VERSION ""

NS_ :

BS_:
BU_: BMSHV BMSLV SMUR SMUF SW VCU PCU LEM EBS IMU

BO_ 8 Arduino1: 8 IMU
   SG_ temp_1 : 0|32@1- (1,0) [0|0] "C" VCU
   SG_ temp_2 : 32|32@1- (1,0) [0|0] "C" VCU

BO_ 20 LVError: 1 BMSLV
   SG_ error_lv : 0|8@1+ (1,0) [0|1] "" Vector__XXX

BO_ 32 ResGO: 1 VCU
   SG_ go_signal : 0|1@1+ (1,0) [0|1] "" Vector__XXX

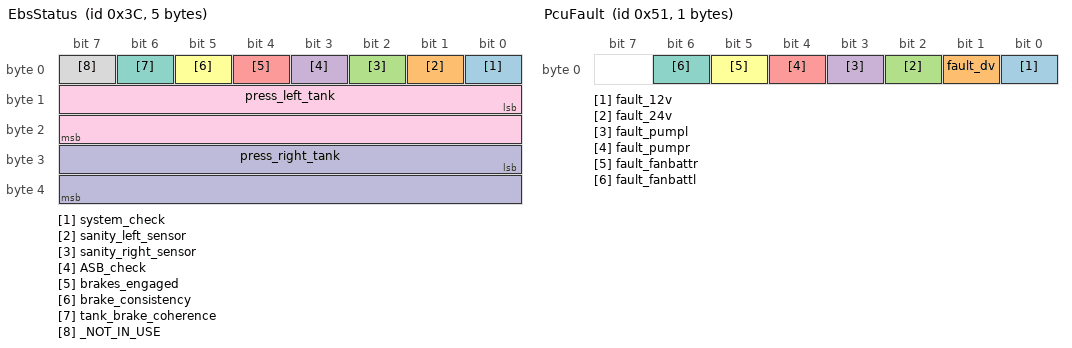
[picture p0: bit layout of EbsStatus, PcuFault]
BO_ 60 EbsStatus: 5 EBS
   SG_ system_check : 0|1@1+ (1,0) [0|1] "" Vector__XXX
   SG_ sanity_left_sensor : 1|1@1+ (1,0) [0|1] "" Vector__XXX
   SG_ sanity_right_sensor : 2|1@1+ (1,0) [0|1] "" Vector__XXX
   SG_ ASB_check : 3|1@1+ (1,0) [0|1] "" Vector__XXX
   SG_ brakes_engaged : 4|1@1+ (1,0) [0|1] "" Vector__XXX
   SG_ brake_consistency : 5|1@1+ (1,0) [0|1] "" Vector__XXX
   SG_ tank_brake_coherence : 6|1@1+ (1,0) [0|1] "" Vector__XXX
   SG_ _NOT_IN_USE : 7|1@1+ (1,0) [0|0] "" Vector__XXX
   SG_ press_left_tank : 8|16@1+ (0.001,0) [0|10] "Bar" Vector__XXX
   SG_ press_right_tank : 24|16@1+ (0.001,0) [0|10] "Bar" Vector__XXX

BO_ 65 Asms: 1 PCU
   SG_ Asms_sens : 0|1@1+ (1,0) [0|1] "High" Vector__XXX

BO_ 66 Asms_ack: 1 VCU
   SG_ Asms_sens : 0|1@1+ (1,0) [0|1] "High" Vector__XXX

BO_ 71 CarMission: 1 SW
   SG_ Mission : 0|3@1+ (1,0) [0|7] "" VCU

BO_ 81 PcuFault: 1 PCU
   SG_ fault_12v : 0|1@1+ (1,0) [0|1] "on" Vector__XXX
   SG_ fault_dv : 1|1@1+ (1,0) [0|1] "on" Vector__XXX
   SG_ fault_24v : 2|1@1+ (1,0) [0|1] "on" Vector__XXX
   SG_ fault_pumpl : 3|1@1+ (1,0) [0|1] "on" Vector__XXX
   SG_ fault_pumpr : 4|1@1+ (1,0) [0|1] "on" Vector__XXX
   SG_ fault_fanbattr : 5|1@1+ (1,0) [0|1] "on" Vector__XXX
   SG_ fault_fanbattl : 6|1@1+ (1,0) [0|1] "on" Vector__XXX

BO_ 82 Paddle: 1 SW
   SG_ regen : 0|8@1+ (1,0) [0|100] "%" VCU

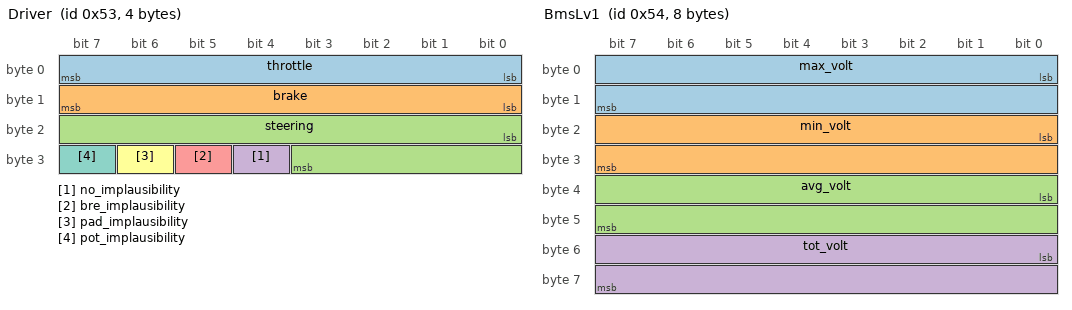
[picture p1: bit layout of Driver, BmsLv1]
BO_ 83 Driver: 4 SMUF
   SG_ throttle : 0|8@1+ (1,0) [0|100] "%" VCU
   SG_ brake : 8|8@1+ (1,0) [0|100] "%" VCU
   SG_ steering : 16|12@1- (1,0) [-120|120] "deg" VCU
   SG_ no_implausibility : 28|1@1+ (1,0) [0|0] "" Vector__XXX
   SG_ bre_implausibility : 29|1@1+ (1,0) [0|0] "" Vector__XXX
   SG_ pad_implausibility : 30|1@1+ (1,0) [0|0] "" Vector__XXX
   SG_ pot_implausibility : 31|1@1+ (1,0) [0|0] "" Vector__XXX

BO_ 84 BmsLv1: 8 BMSLV
   SG_ max_volt : 0|16@1+ (0.1,0) [0|0] "mV" VCU
   SG_ min_volt : 16|16@1+ (0.1,0) [0|0] "mV" VCU
   SG_ avg_volt : 32|16@1+ (0.1,0) [0|0] "mV" VCU
   SG_ tot_volt : 48|16@1+ (0.01,0) [0|100] "V" Vector__XXX

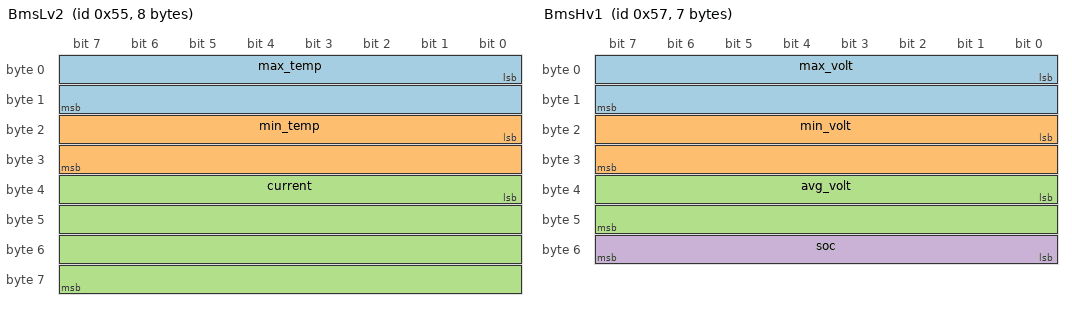
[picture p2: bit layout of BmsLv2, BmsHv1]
BO_ 85 BmsLv2: 8 BMSLV
   SG_ max_temp : 0|16@1+ (0.1,0) [0|0] "C" VCU
   SG_ min_temp : 16|16@1+ (0.1,0) [0|0] "C" VCU
   SG_ current : 32|32@1+ (0.1,0) [0|0] "mA" VCU

BO_ 87 BmsHv1: 7 BMSHV
   SG_ max_volt : 0|16@1+ (0.1,0) [0|0] "mV" VCU
   SG_ min_volt : 16|16@1+ (0.1,0) [0|0] "mV" VCU
   SG_ avg_volt : 32|16@1+ (0.1,0) [0|0] "mV" VCU
   SG_ soc : 48|8@1+ (1,0) [0|100] "%" VCU

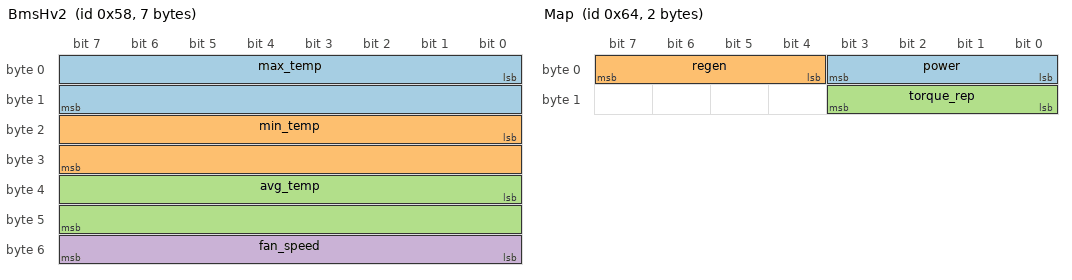
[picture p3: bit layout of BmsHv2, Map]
BO_ 88 BmsHv2: 7 BMSHV
   SG_ max_temp : 0|16@1+ (1,0) [0|0] "C" VCU
   SG_ min_temp : 16|16@1+ (1,0) [0|0] "C" VCU
   SG_ avg_temp : 32|16@1+ (1,0) [0|0] "C" VCU
   SG_ fan_speed : 48|8@1+ (1,0) [0|100] "%" VCU

BO_ 96 Imu1: 8 IMU
   SG_ acc_x : 0|32@1- (1,0) [0|0] "m/s^2" VCU
   SG_ acc_y : 32|32@1- (1,0) [0|0] "m/s^2" VCU

BO_ 97 Imu2: 8 IMU
   SG_ acc_z : 0|32@1- (1,0) [0|0] "m/s^2" VCU
   SG_ omega_x : 32|32@1- (1,0) [0|0] "rad/s" VCU

BO_ 98 Imu3: 8 IMU
   SG_ omega_y : 0|32@1- (1,0) [0|0] "rad/s" VCU
   SG_ omega_z : 32|32@1- (1,0) [0|0] "rad/s" VCU

BO_ 99 IMUCalib: 1 IMU
   SG_ start_imu_calibration : 0|1@1+ (1,0) [0|0] "" Vector__XXX

BO_ 100 Map: 2 SW
   SG_ power : 0|4@1+ (1,0) [1|12] "map" VCU
   SG_ regen : 4|4@1+ (1,0) [1|12] "map" VCU
   SG_ torque_rep : 8|4@1+ (1,0) [0|12] "map" Vector__XXX

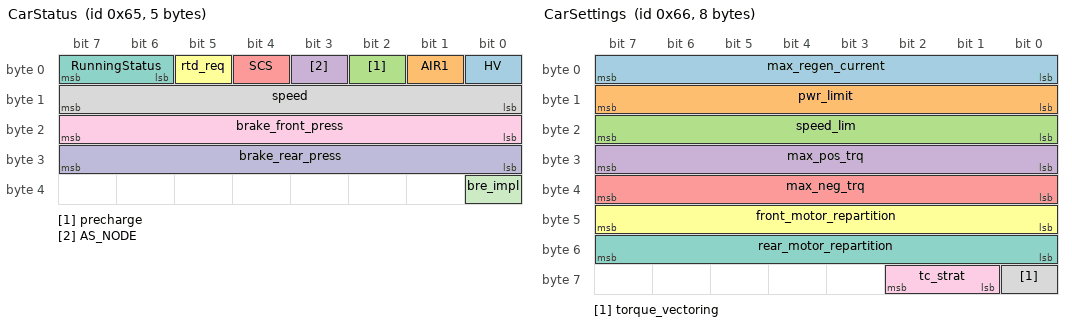
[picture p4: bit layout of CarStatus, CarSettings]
BO_ 101 CarStatus: 5 VCU
   SG_ HV : 0|1@1+ (1,0) [0|0] " Off/On" Vector__XXX
   SG_ AIR1 : 1|1@1+ (1,0) [0|0] " Closed/Open" Vector__XXX
   SG_ precharge : 2|1@1+ (1,0) [0|0] " Closed/Open" Vector__XXX
   SG_ AS_NODE : 3|1@1+ (1,0) [0|0] " Open/Closed" Vector__XXX
   SG_ SCS : 4|1@1+ (1,0) [0|0] " Open/Closed" Vector__XXX
   SG_ rtd_req : 5|1@1+ (1,0) [0|0] " Open/Closed" Vector__XXX
   SG_ RunningStatus : 6|2@1+ (1,0) [0|3] " Phase" Vector__XXX
   SG_ speed : 8|8@1+ (1,0) [0|0] " km/h" Vector__XXX
   SG_ brake_front_press : 16|8@1+ (0.25,0) [0|60] "Bar" Vector__XXX
   SG_ brake_rear_press : 24|8@1+ (0.25,0) [0|60] "Bar" Vector__XXX
   SG_ bre_impl : 32|1@1+ (1,0) [0|1] "" Vector__XXX

BO_ 102 CarSettings: 8 VCU
   SG_ max_regen_current : 0|8@1+ (1,0) [0|150] "A" Vector__XXX
   SG_ pwr_limit : 8|8@1+ (1,0) [0|80] "kW" Vector__XXX
   SG_ speed_lim : 16|8@1+ (1,0) [0|0] "krpm" Vector__XXX
   SG_ max_pos_trq : 24|8@1+ (1,0) [0|0] "Nm" Vector__XXX
   SG_ max_neg_trq : 32|8@1- (1,0) [0|0] "Nm" Vector__XXX
   SG_ front_motor_repartition : 40|8@1+ (1,0) [0|0] "%" Vector__XXX
   SG_ rear_motor_repartition : 48|8@1+ (1,0) [0|0] "%" Vector__XXX
   SG_ torque_vectoring : 56|1@1+ (1,0) [0|1] "on" Vector__XXX
   SG_ tc_strat : 57|2@1+ (1,0) [0|2] "" Vector__XXX

BO_ 104 CheckASBReq: 1 VCU
   SG_ req : 0|1@1+ (1,0) [0|1] "" Vector__XXX
   SG_ reqAck : 1|1@1+ (1,0) [0|1] "" Vector__XXX

BO_ 105 EbsBrakeReq: 1 VCU
   SG_ req : 0|1@1+ (1,0) [0|2] "" Vector__XXX

BO_ 106 ResStatus: 1 Vector__XXX
   SG_ data : 0|1@1+ (1,0) [0|2] "" Vector__XXX

BO_ 112 LapStart: 1 SW
   SG_ start : 0|8@1+ (1,0) [0|1] "start" Vector__XXX

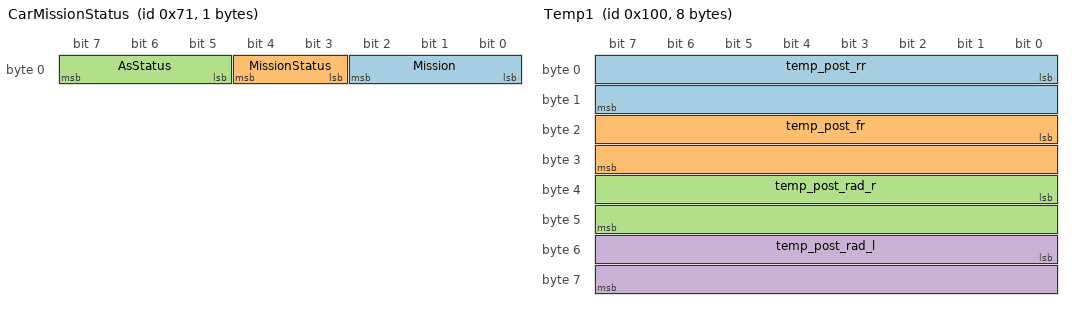
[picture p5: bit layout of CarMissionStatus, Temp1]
BO_ 113 CarMissionStatus: 1 VCU
   SG_ Mission : 0|3@1+ (1,0) [0|7] "" SW
   SG_ MissionStatus : 3|2@1+ (1,0) [0|2] "" SW
   SG_ AsStatus : 5|3@1+ (1,0) [0|7] "" SW

BO_ 128 Imu4: 8 IMU
   SG_ mag_x : 0|32@1- (1,0) [0|0] "m/s^2" VCU
   SG_ mag_y : 32|32@1- (1,0) [0|0] "m/s^2" VCU

BO_ 129 Imu5: 8 IMU
   SG_ mag_z : 0|32@1- (1,0) [0|0] "m/s^2" VCU
   SG_ null : 32|32@1- (1,0) [0|0] "rad/s" VCU

BO_ 256 Temp1: 8 SMUR
   SG_ temp_post_rr : 0|16@1+ (1,0) [0|0] "C" VCU
   SG_ temp_post_fr : 16|16@1+ (1,0) [0|0] "C" VCU
   SG_ temp_post_rad_r : 32|16@1+ (1,0) [0|0] "C" VCU
   SG_ temp_post_rad_l : 48|16@1+ (1,0) [0|0] "C" VCU

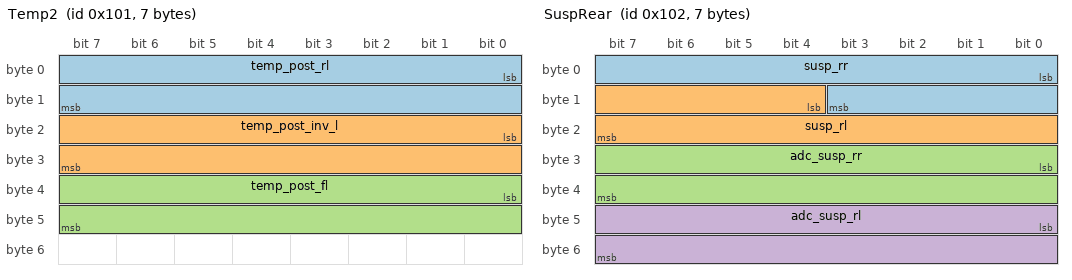
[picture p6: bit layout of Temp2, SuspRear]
BO_ 257 Temp2: 7 SMUR
   SG_ temp_post_rl : 0|16@1+ (1,0) [0|0] "C" VCU
   SG_ temp_post_inv_l : 16|16@1+ (1,0) [0|0] "C" VCU
   SG_ temp_post_fl : 32|16@1+ (1,0) [0|0] "C" VCU

BO_ 258 SuspRear: 7 SMUR
   SG_ susp_rr : 0|12@1+ (0.1,0) [0|0] "mm" VCU
   SG_ susp_rl : 12|12@1+ (0.1,0) [0|0] "mm" VCU
   SG_ adc_susp_rr : 24|16@1+ (1,0) [0|0] "" VCU
   SG_ adc_susp_rl : 40|16@1+ (1,0) [0|0] "" VCU

BO_ 259 RESERVED2: 0 Vector__XXX

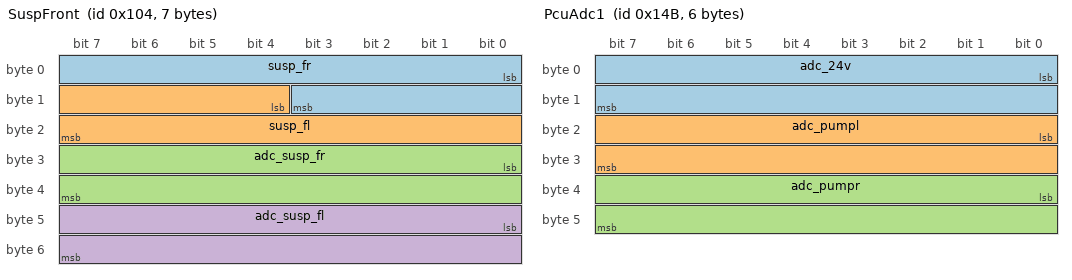
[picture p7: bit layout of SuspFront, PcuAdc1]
BO_ 260 SuspFront: 7 SMUF
   SG_ susp_fr : 0|12@1+ (0.1,0) [0|0] "mm" VCU
   SG_ susp_fl : 12|12@1+ (0.1,0) [0|0] "mm" VCU
   SG_ adc_susp_fr : 24|16@1+ (1,0) [0|0] "" VCU
   SG_ adc_susp_fl : 40|16@1+ (1,0) [0|0] "" VCU

BO_ 261 TempFrontR: 3 SMUF
   SG_ temp_post_inv_r : 0|10@1+ (1,0) [0|0] "C" Vector__XXX
   SG_ temp_post_emb : 10|10@1+ (1,0) [0|0] "C" Vector__XXX

BO_ 264 HydraulicPressure: 8 VCU
   SG_ PressFront : 0|32@1+ (1,0) [0|0] "Bar" EBS
   SG_ PressRear : 32|32@1+ (1,0) [0|0] "Bar" EBS

BO_ 277 TempImu: 4 IMU
   SG_ temp_pump_right : 0|16@1+ (1,0) [0|0] "C" VCU
   SG_ temp_pump_left : 16|16@1+ (1,0) [0|0] "C" VCU

BO_ 288 InvVolt: 2 VCU
   SG_ car_voltage : 0|16@1+ (1,0) [0|600] "V" VCU

BO_ 304 Pcu: 7 VCU
   SG_ mode M : 0|2@1+ (1,0) [0|2] "" Vector__XXX
   SG_ rf m1 : 2|1@1+ (1,0) [0|1] "on" Vector__XXX
   SG_ enable_dv m2 : 2|1@1+ (1,0) [0|1] "on" Vector__XXX
   SG_ enable_embedded m2 : 3|1@1+ (1,0) [0|1] "on" Vector__XXX

BO_ 305 Calib: 1 SW
   SG_ position M : 0|8@1+ (1,0) [0|1] "high" SMUF

BO_ 306 CalibAck: 1 SMUF
   SG_ position M : 0|8@1+ (1,0) [0|1] "high" SW

BO_ 307 PcuSwControl: 1 SW
   SG_ pump : 0|1@1+ (1,0) [0|1] "" VCU
   SG_ fan : 1|1@1+ (1,0) [0|1] "" VCU

BO_ 308 PcuRfAck: 1 PCU
   SG_ rf_signalAck : 0|1@1+ (1,0) [0|1] "on" VCU

BO_ 310 EmbeddedAliveCheck: 0 VCU

BO_ 328 CalibRegen: 1 SW
   SG_ arrive M : 0|8@1+ (1,0) [0|1] "arrive" SMUF

BO_ 329 CalibRegenAck: 1 SMUF
   SG_ arrive M : 0|8@1+ (1,0) [0|1] "arrive" SW

BO_ 331 PcuAdc1: 6 PCU
   SG_ adc_24v : 0|16@1+ (0.001,0) [0|30] "A" Vector__XXX
   SG_ adc_pumpl : 16|16@1+ (0.001,0) [0|30] "A" Vector__XXX
   SG_ adc_pumpr : 32|16@1+ (0.001,0) [0|30] "A" Vector__XXX

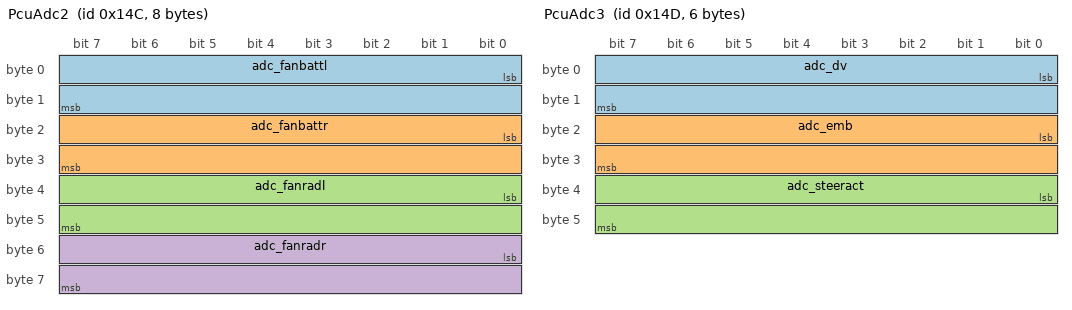
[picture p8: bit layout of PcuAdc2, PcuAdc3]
BO_ 332 PcuAdc2: 8 PCU
   SG_ adc_fanbattl : 0|16@1+ (0.001,0) [0|30] "A" Vector__XXX
   SG_ adc_fanbattr : 16|16@1+ (0.001,0) [0|30] "A" Vector__XXX
   SG_ adc_fanradl : 32|16@1+ (0.001,0) [0|30] "A" Vector__XXX
   SG_ adc_fanradr : 48|16@1+ (0.001,0) [0|30] "A" Vector__XXX

BO_ 333 PcuAdc3: 6 PCU
   SG_ adc_dv : 0|16@1+ (0.001,0) [0|30] "A" Vector__XXX
   SG_ adc_emb : 16|16@1+ (0.001,0) [0|30] "A" Vector__XXX
   SG_ adc_steeract : 32|16@1+ (0.001,0) [0|30] "A" Vector__XXX

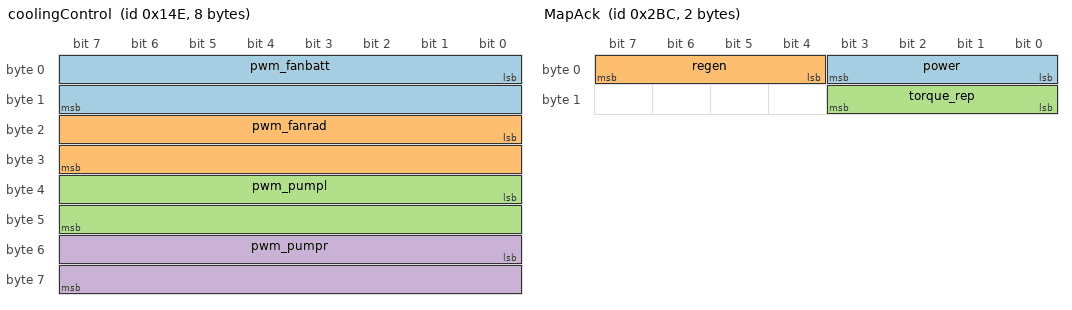
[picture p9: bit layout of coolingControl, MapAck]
BO_ 334 coolingControl: 8 PCU
   SG_ pwm_fanbatt : 0|16@1+ (1,0) [0|65535] "" Vector__XXX
   SG_ pwm_fanrad : 16|16@1+ (1,0) [0|65535] "" Vector__XXX
   SG_ pwm_pumpl : 32|16@1+ (1,0) [0|65535] "" Vector__XXX
   SG_ pwm_pumpr : 48|16@1+ (1,0) [0|65535] "" Vector__XXX

BO_ 420 Balancing: 1 BMSLV
   SG_ balancing_lv : 0|8@1- (1,0) [0|1] "" BMSLV

BO_ 600 DisplayACK: 1 SW
   SG_ UART_fault : 0|1@1+ (1,0) [0|1] "" SW

BO_ 700 MapAck: 2 VCU
   SG_ power : 0|4@1+ (1,0) [1|12] "map" VCU
   SG_ regen : 4|4@1+ (1,0) [1|12] "map" VCU
   SG_ torque_rep : 8|4@1+ (1,0) [0|12] "map" Vector__XXX

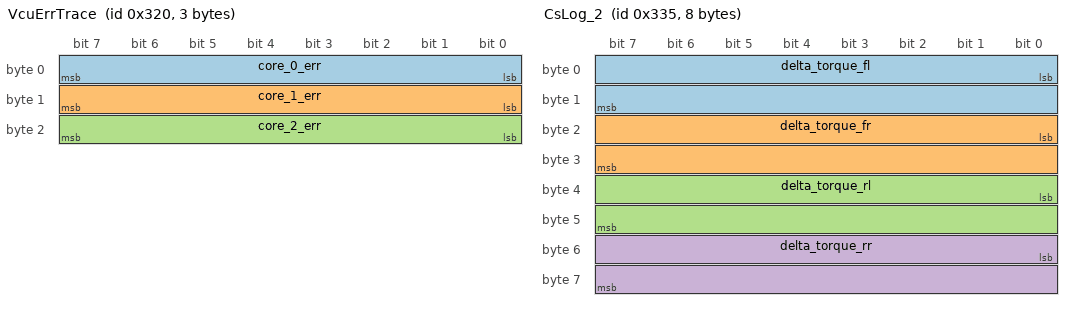
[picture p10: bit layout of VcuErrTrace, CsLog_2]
BO_ 800 VcuErrTrace: 3 VCU
   SG_ core_0_err : 0|8@1+ (1,0) [0|255] "" VCU
   SG_ core_1_err : 8|8@1+ (1,0) [0|255] "" VCU
   SG_ core_2_err : 16|8@1+ (1,0) [0|255] "" VCU

BO_ 820 CsLog_1: 8 VCU
   SG_ yr_ref : 0|32@1- (1,0) [-5|5] " rad/s" Vector__XXX
   SG_ yaw_moment : 32|32@1- (1,0) [-4000|4000] " Nm" Vector__XXX

BO_ 821 CsLog_2: 8 VCU
   SG_ delta_torque_fl : 0|16@1- (1,0) [0|0] " Nmm" Vector__XXX
   SG_ delta_torque_fr : 16|16@1- (1,0) [0|0] " Nmm" Vector__XXX
   SG_ delta_torque_rl : 32|16@1- (1,0) [0|0] " Nmm" Vector__XXX
   SG_ delta_torque_rr : 48|16@1- (1,0) [0|0] " Nmm" Vector__XXX

BO_ 822 CsLog_3: 8 VCU
   SG_ vx : 0|32@1+ (0.001,0) [0|50] " m/s" Vector__XXX

BO_ 869 BmsLvCellControl: 1 BMSLV
   SG_ enable : 0|1@1+ (1,0) [0|1] "" BMSLV

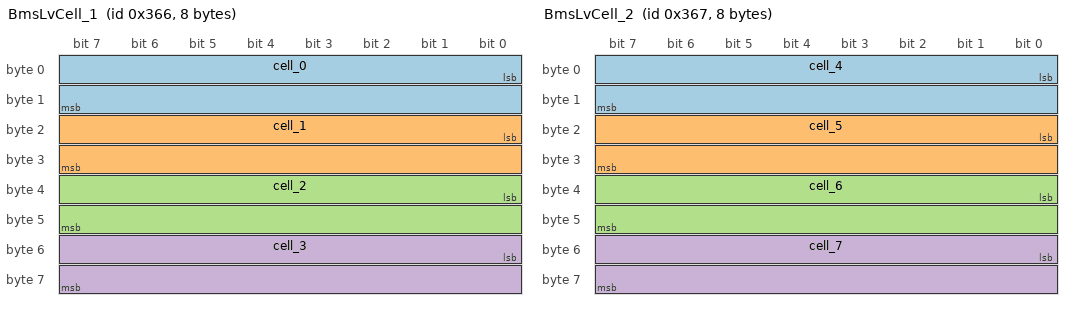
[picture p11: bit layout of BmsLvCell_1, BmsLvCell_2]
BO_ 870 BmsLvCell_1: 8 BMSLV
   SG_ cell_0 : 0|16@1+ (0.1,0) [0|0] "mV" BMSLV
   SG_ cell_1 : 16|16@1+ (0.1,0) [0|0] "mV" BMSLV
   SG_ cell_2 : 32|16@1+ (0.1,0) [0|0] "mV" BMSLV
   SG_ cell_3 : 48|16@1+ (0.1,0) [0|0] "mV" BMSLV

BO_ 871 BmsLvCell_2: 8 BMSLV
   SG_ cell_4 : 0|16@1+ (0.1,0) [0|0] "mV" BMSLV
   SG_ cell_5 : 16|16@1+ (0.1,0) [0|0] "mV" BMSLV
   SG_ cell_6 : 32|16@1+ (0.1,0) [0|0] "mV" BMSLV
   SG_ cell_7 : 48|16@1+ (0.1,0) [0|0] "mV" BMSLV

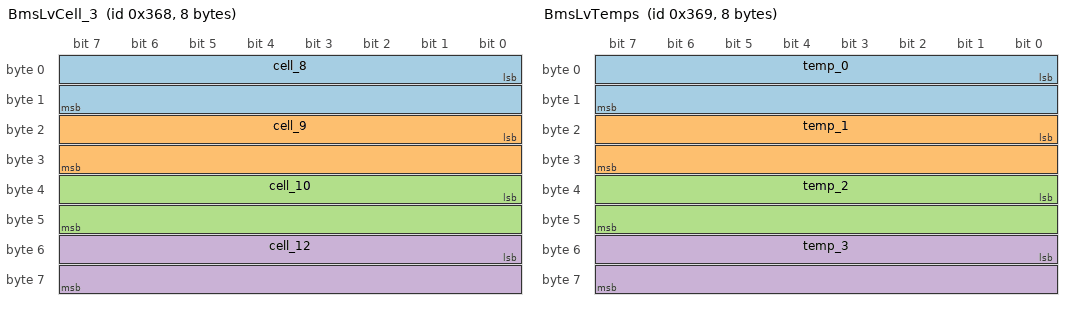
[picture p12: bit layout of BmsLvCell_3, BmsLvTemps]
BO_ 872 BmsLvCell_3: 8 BMSLV
   SG_ cell_8 : 0|16@1+ (0.1,0) [0|0] "mV" BMSLV
   SG_ cell_9 : 16|16@1+ (0.1,0) [0|0] "mV" BMSLV
   SG_ cell_10 : 32|16@1+ (0.1,0) [0|0] "mV" BMSLV
   SG_ cell_12 : 48|16@1+ (0.1,0) [0|0] "mV" BMSLV

BO_ 873 BmsLvTemps: 8 BMSLV
   SG_ temp_0 : 0|16@1+ (0.1,0) [0|0] "C" BMSLV
   SG_ temp_1 : 16|16@1+ (0.1,0) [0|0] "C" BMSLV
   SG_ temp_2 : 32|16@1+ (0.1,0) [0|0] "C" BMSLV
   SG_ temp_3 : 48|16@1+ (0.1,0) [0|0] "C" BMSLV

BO_ 962 Lem: 8 LEM
   SG_ current : 7|32@0+ (1,-2147483648) [0|0] "mA" VCU

CM_ SG_ 82 regen "% of regen paddle travel";
CM_ SG_ 83 throttle "% of throttle";
CM_ SG_ 83 brake "% of brake pedal";
CM_ SG_ 83 steering "Steering angle in milli radians";
CM_ SG_ 87 max_volt "Maximum cell voltage in mv";
CM_ SG_ 87 min_volt "Minimum cell voltage in mv";
CM_ SG_ 87 avg_volt "Average cell voltage in mv";
CM_ SG_ 87 soc "HV battery SOC in %";
CM_ SG_ 88 max_temp "Maximum cell temperature in celsius";
CM_ SG_ 88 min_temp "Minimum cell temperature in celsius";
CM_ SG_ 88 fan_speed "% of HV battery fan speed";
CM_ SG_ 96 acc_x "Acceleration on x axis in m/s^2";
CM_ SG_ 96 acc_y "Acceleration on y axis in m/s^2";
CM_ SG_ 97 acc_z "Acceleration on z axis in m/s^2";
CM_ SG_ 97 omega_x "Angular speed on x axis in rad/s";
CM_ SG_ 98 omega_y "Angular speed on x axis in rad/s";
CM_ SG_ 98 omega_z "Angular speed on x axis in rad/s";
CM_ BO_ 99 "RESERVER FOR IMU mask - DO NOT USE";
CM_ SG_ 100 power "Map selected number";
CM_ SG_ 100 regen "Map selected for regen braking";
CM_ SG_ 100 torque_rep "Map selected for torque repeartition";
CM_ SG_ 102 max_regen_current "Maximum Regen Current";
CM_ SG_ 102 pwr_limit "Maximum power limit";
CM_ SG_ 102 speed_lim "Maximum Speed Limit";
CM_ SG_ 102 max_pos_trq "Maximum Positive Torque";
CM_ SG_ 102 max_neg_trq "Maximum Negative Torque";
CM_ SG_ 102 front_motor_repartition "Torque Repartition Front";
CM_ SG_ 102 rear_motor_repartition "Torque Repartition Rear";
CM_ SG_ 102 torque_vectoring "Torque Vectoring enabled";
CM_ SG_ 258 susp_rr "RR suspension travel in mm";
CM_ SG_ 258 susp_rl "RL suspension travel in mm";
CM_ BO_ 259 "RESERVER FOR SMU mask - DO NOT USE";
CM_ SG_ 260 susp_fr "FR suspension travel in mm";
CM_ SG_ 260 susp_fl "FL suspension travel in mm";
CM_ BO_ 264 "Hydraulic Brakes Pressures";
CM_ SG_ 264 PressFront "0 means fault";
CM_ SG_ 264 PressRear "0 means fault";
CM_ SG_ 288 car_voltage "Voltage seen from car side (inverter) in volts";
CM_ SG_ 305 position "Set calibration of rest value (0) or 100% (1)";
CM_ SG_ 962 current "Current seen from LEM on car side (PDBe";

VAL_ 20 error_lv 1 "Error" 0 "No_Error";
VAL_ 71 Mission 7 "dv_inspection" 6 "dv_ebs_test" 5 "dv_trackdrive" 4 "dv_autocross" 3 "dv_skidpad" 2 "dv_acceleration" 1 "manualy" 0 "none";
VAL_ 101 RunningStatus 3 "Running" 2 "Ts Ready" 1 "Precharge started" 0 "System off";
VAL_ 101 bre_impl 1 "On" 0 "Off";
VAL_ 113 Mission 7 "dv_inspection" 6 "dv_ebs_test" 5 "dv_trackdrive" 4 "dv_autocross" 3 "dv_skidpad" 2 "dv_acceleration" 1 "manualy" 0 "none";
VAL_ 113 MissionStatus 2 "Mission_finished" 1 "Mission_running" 0 "Mission_not_running";
VAL_ 113 AsStatus 5 "finish" 4 "emergency_brake" 3 "driving" 2 "ready" 1 "off";
VAL_ 307 pump 1 "On" 0 "Off";
VAL_ 307 fan 1 "On" 0 "Off";
VAL_ 420 balancing_lv 1 "On" 0 "Off";

SIG_VALTYPE_ 8 temp_1 : 1;
SIG_VALTYPE_ 8 temp_2 : 1;
SIG_VALTYPE_ 96 acc_x : 1;
SIG_VALTYPE_ 96 acc_y : 1;
SIG_VALTYPE_ 97 acc_z : 1;
SIG_VALTYPE_ 97 omega_x : 1;
SIG_VALTYPE_ 98 omega_y : 1;
SIG_VALTYPE_ 98 omega_z : 1;
SIG_VALTYPE_ 820 yr_ref : 1;
SIG_VALTYPE_ 820 yaw_moment : 1;
SIG_VALTYPE_ 822 vx : 1;

SG_MUL_VAL_ 304 rf mode 1-1;
SG_MUL_VAL_ 304 enable_dv mode 2-2;
SG_MUL_VAL_ 304 enable_embedded mode 2-2;
